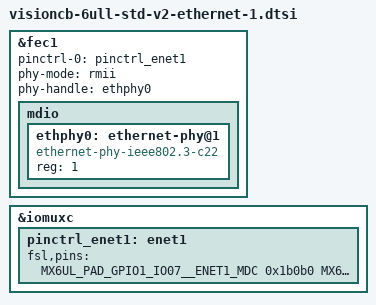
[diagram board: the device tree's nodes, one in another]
/*
 * This program is free software; you can redistribute it and/or modify
 * it under the terms of the GNU General Public License version 2 as
 * published by the Free Software Foundation.
 */

/* Ethernet 1 */
&fec1 {
	pinctrl-names = "default";
	pinctrl-0 = <&pinctrl_enet1>;
	phy-mode = "rmii";
	phy-handle = <&ethphy0>;
	status = "okay";

	mdio {
		#address-cells = <1>;
		#size-cells = <0>;

		ethphy0: ethernet-phy@1 {
			compatible = "ethernet-phy-ieee802.3-c22";
			reg = <1>;
		};
	};
};

/* IO multiplexing */
&iomuxc {
	/* Ethernet 1 */
	pinctrl_enet1: enet1 {
		fsl,pins = <
			MX6UL_PAD_GPIO1_IO07__ENET1_MDC         0x1b0b0
			MX6UL_PAD_GPIO1_IO06__ENET1_MDIO        0x1f829
			MX6UL_PAD_ENET1_RX_EN__ENET1_RX_EN      0x1b0b0
			MX6UL_PAD_ENET1_RX_ER__ENET1_RX_ER      0x1b0b0
			MX6UL_PAD_ENET1_RX_DATA0__ENET1_RDATA00 0x1b0b0
			MX6UL_PAD_ENET1_RX_DATA1__ENET1_RDATA01 0x1b0b0
			MX6UL_PAD_ENET1_TX_EN__ENET1_TX_EN      0x1b0b0
			MX6UL_PAD_ENET1_TX_DATA0__ENET1_TDATA00 0x1b0b0
			MX6UL_PAD_ENET1_TX_DATA1__ENET1_TDATA01 0x1b0b0
			MX6UL_PAD_ENET1_TX_CLK__ENET1_REF_CLK1  0x400010a9
		>;
	};
};
